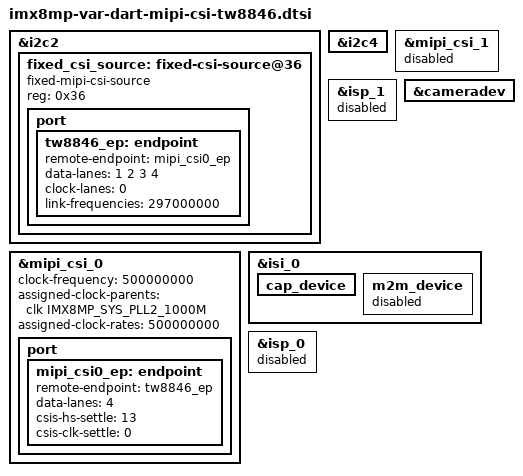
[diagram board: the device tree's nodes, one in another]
// SPDX-License-Identifier: (GPL-2.0+ OR MIT)
/*
 * Copyright 2026 Variscite Ltd.
 */

/*
 * TW8846 video processor feeding MIPI-CSI into mipi_csi_0 (physical
 * "CSI1", per the csi0 = &mipi_csi_0 alias in imx8mp.dtsi), 4 lanes,
 * YUV422, 1920x1080@60. TW8846 itself is fully configured and streamed
 * by an external microcontroller over its own I2C bus - Linux never
 * talks to it. Only the receiver side (mipi_csi_0 -> isi_0) is wired
 * up here, per the ISI (not ISP) path since YUV422 is already a
 * formed pixel format, not raw Bayer needing demosaic.
 *
 * The earlier 2-lane/30fps diagnostic detour is reverted here. Its
 * premise - that no working 4-lane reference exists in this tree -
 * was wrong: imx8mp-var-dart-dt8mcustomboard-basler-isp0.dtsi (still
 * earlier in this file's own include chain, via
 * imx8mp-var-dart-sonata-basler-isp0.dts) drives this exact
 * mipi_csi_0 on this exact SOM at data-lanes = <4>, 750Mbps/lane,
 * csis-hs-settle = <16>. Only the OV5640 configs are 2-lane. So
 * 4 lanes is proven on this receiver and this SOM, and lane count is
 * not the variable that explains MIPI_CSIS_DPHYSTATUS never showing
 * Stop State - look at the transmit side (whether the TW8846's
 * microcontroller has actually been told to bring up 4 lanes and
 * assert LP-11) and at the physical lane routing on the Deadeye
 * carrier before suspecting the receiver again.
 *
 * Pixel format itself is not a devicetree property on this driver -
 * imx8-mipi-csi2-sam.c negotiates it purely at runtime via V4L2 subdev
 * s_fmt (mipi_csis_formats[] in the driver, YUYV8_2X8 is index 0 / the
 * fallback default). Nothing below needs to change between RGB888 and
 * YUV422 except this comment and, eventually, csis-hs-settle/
 * csis-clk-settle once the actual YUV422 lane bit rate is measured -
 * PRBS sweep to determine that is deferred for now.
 *
 * "tw8846" below is NOT a TW8846 driver - it's fixed-csi-source
 * (drivers/media/i2c/fixed-csi-source.c), a stub v4l2_subdev that
 * performs no register access at all. It exists only because
 * register_sensor_entities() in
 * drivers/staging/media/imx/imx8-media-dev.c requires
 * of_find_i2c_device_by_node() to find a real, bound i2c_client for
 * mipi_csi_0's remote endpoint before it will link the media graph -
 * otherwise the whole mxc-md platform driver returns -EPROBE_DEFER
 * forever and no /dev/videoX ever appears, regardless of whether
 * csis_get_remote_subdev() in imx8-mipi-csi2-sam.c would separately
 * also fail. The i2c reg address below is a bookkeeping placeholder
 * only - no transactions are ever issued to it.
 *
 * TODO before this is usable:
 * - csis-hs-settle/csis-clk-settle below are placeholders, not
 *   computed from the TW8846's actual MIPI D-PHY lane bit rate -
 *   imx8-mipi-csi2-sam.c reads these as raw register values with no
 *   auto-calculation, unlike some other NXP CSI receiver drivers.
 *   Note the full 256x4 sweep of these already found no lock, so they
 *   are unlikely to be the remaining blocker on their own.
 *
 * mipi_csi_0's clock-frequency/assigned-clocks are restored to the
 * imx8mp.dtsi default (500MHz) rather than the Basler ISP0 dtsi's
 * 266MHz override (still earlier in this file's include chain, and
 * would otherwise silently persist since nothing after it touched
 * it) - 266MHz was presumably tuned for Basler's own pixel rate, not
 * verified here for 1080p60 YUV422. 500MHz comfortably clears the
 * ~148.5MPix/s this format+resolution needs.
 */

&i2c2 {
	/delete-node/ov5640_mipi@3c;
	/delete-node/basler_camera@36;

	/*
	 * Bookkeeping-only node - see the fixed-csi-source explanation
	 * above. No i2c transactions are ever issued to 0x36; reusing the
	 * address just-freed from basler_camera@36 above.
	 */
	fixed_csi_source: fixed-csi-source@36 {
		compatible = "fixed-mipi-csi-source";
		reg = <0x36>;

		port {
			tw8846_ep: endpoint {
				remote-endpoint = <&mipi_csi0_ep>;
				data-lanes = <1 2 3 4>;
				clock-lanes = <0>;
				link-frequencies = /bits/ 64 <297000000>;	/* 594 Mbps/lane YUV422 1080p60, DDR/2 */
			};
		};
	};
};

/*
 * The Basler ISP0 dtsi earlier in the include chain also brings up a
 * second, unrelated Basler pipeline on i2c4 -> mipi_csi_1 -> isp_1.
 * Nothing on the Deadeye carrier is wired to CSI2, so that pipeline
 * only probes, fails, and adds noise to dmesg and to the media graph
 * while the CSI1 bring-up above is being debugged. Tear it down.
 *
 * port@1 must be deleted along with the i2c node: unlike mipi_csi_0
 * above - where this file re-points the endpoint at tw8846_ep -
 * nothing reassigns mipi_csi_1's remote-endpoint, so deleting
 * basler_camera@36 alone leaves it referencing a dangling
 * &basler_ep_1 and dtc fails the build outright.
 */
&i2c4 {
	/delete-node/basler_camera@36;
};

&mipi_csi_1 {
	status = "disabled";
	/*
	 * #address-cells/#size-cells come from the base board file purely
	 * to address port@1; with that gone they only earn an
	 * avoid_unnecessary_addr_size warning from dtc.
	 */
	/delete-property/ #address-cells;
	/delete-property/ #size-cells;
	/delete-node/ port@1;
};

&isp_1 {
	status = "disabled";
};

&mipi_csi_0 {
	status = "okay";
	clock-frequency = <500000000>;
	assigned-clock-parents = <&clk IMX8MP_SYS_PLL2_1000M>;
	assigned-clock-rates = <500000000>;

	port {
		mipi_csi0_ep: endpoint {
			remote-endpoint = <&tw8846_ep>;
			data-lanes = <4>;
			/*
			 * Ths_settle for a 594 Mbps lane rate, per the
			 * formula the mainline driver for this same Samsung
			 * CSIS IP uses (drivers/media/platform/nxp/
			 * imx-mipi-csis.c): (lane_rate - 5e6) / 45e6.
			 * That formula reproduces both known-good configs in
			 * this tree exactly - OV5640 at ~297Mbps uses 6, and
			 * Basler at 750Mbps uses 16 - so it is trustworthy
			 * here. 16 was previously copied from Basler on the
			 * mistaken assumption the value transfers between
			 * configs; it does not, it scales with bit rate.
			 * Too large a value makes the receiver sample past
			 * SOT and never begin packet decode, which presents
			 * as zero Frame Start events AND zero error events.
			 */
			csis-hs-settle = <13>;
			csis-clk-settle = <0>;	/* mainline hardcodes 0; the Basler config omits it, same effect */
		};
	};
};

&cameradev {
	status = "okay";
};

&isi_0 {
	status = "okay";

	cap_device {
		status = "okay";
	};

	/*
	 * The base board file (imx8mp-var-dart-dt8mcustomboard.dts) leaves
	 * this enabled by default. With both cap_device and m2m_device
	 * registered against the same physical ISI channel, the m2m
	 * persona (imx8-isi-m2m.c) ends up answering on the video node
	 * instead of the plain capture path (imx8-isi-cap.c) - confirmed
	 * via a kernel stack trace showing v4l2_m2m_ioctl_dqbuf, and via
	 * isi_cap_fmt_init()/mxc_isi_source_fmt_init() never executing
	 * despite streaming appearing to start. m2m's src_f has no live
	 * sensor feed to source from (it expects an OUTPUT-queue-fed
	 * buffer), so it defaults to ISI_4K/ISI_8K (4096x8192) as a
	 * placeholder, misconfiguring the scale engine and stalling
	 * VIDIOC_DQBUF forever. Not needed for a live camera capture path.
	 */
	m2m_device {
		status = "disabled";
	};
};

&isp_0 {
	status = "disabled";
};
